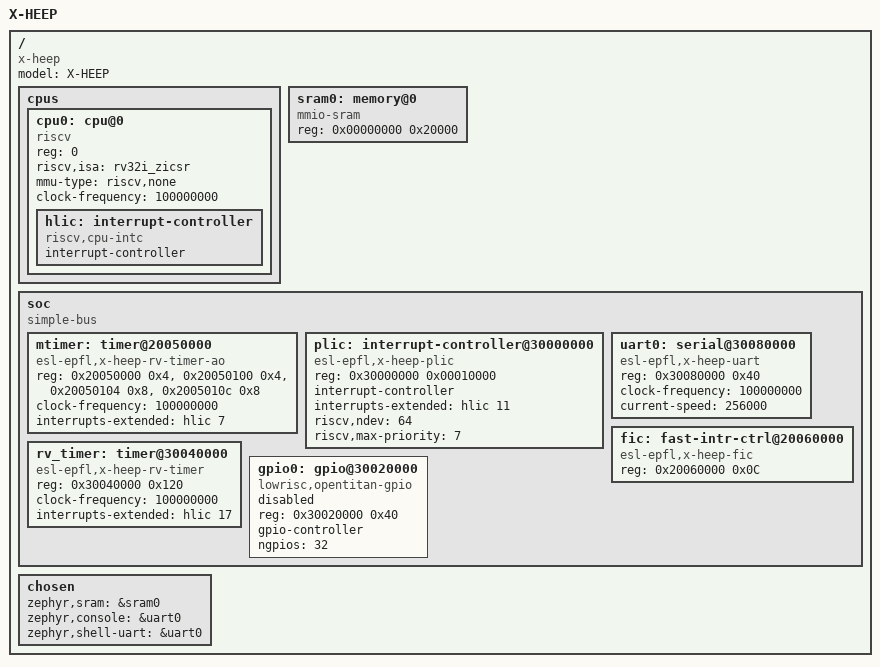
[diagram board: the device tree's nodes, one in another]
/*
 * author: rbatal (rodrigo.batal@gmail.com)
 *
 * X-HEEP Devicetree for Zephyr RTOS (core-agnostic)
 *  Applies to all X-HEEP core variants: cv32e20p, cv32e40p, cv32e40x, cv32e40px
 *
 * Notes:
 *  1 - Custom OpenTitan UART driver (differs from the one in Zephyr sources)
 *  2 - Custom OpenTitan PLIC driver (none available in Zephyr sources)
 */

/ {
	#address-cells = <1>;
	#size-cells = <1>;
	compatible = "x-heep";
	model = "X-HEEP";

	cpus {
		#address-cells = <1>;
		#size-cells = <0>;

		cpu0: cpu@0 {
			device_type = "cpu";
			compatible = "riscv";
			reg = <0>;
			riscv,isa = "rv32i_zicsr";
			mmu-type = "riscv,none";
			clock-frequency = <100000000>;
			status = "okay";

			hlic: interrupt-controller {
				compatible = "riscv,cpu-intc";
				#address-cells = <0>;
				#interrupt-cells = <1>;
				interrupt-controller;
			};
		};
	};

	sram0: memory@0 {
		device_type = "memory";
		compatible = "mmio-sram";
		reg = <0x00000000 0x20000>;  /* 128KB */
	};

	soc {
		#address-cells = <1>;
		#size-cells = <1>;
		compatible = "simple-bus";
		ranges;

		/*
		 * Machine Timer (Always-On domain)
		 * lowRISC rv_timer_ao
		 *
		 * CTRL (0x000) and CFG0 (0x100) are initialized in soc_early_init
		 * (PRE_KERNEL_1) before the riscv_machine_timer driver reads mtime.
		 * The "riscv,machine-timer" fallback compatible is required so that
		 * Zephyr's riscv_machine_timer driver binds to this node via DT_INST.
     *
		 * Interrupt routes through FIC bit 0 (kTimer_1_fic_e) to
		 * irq_i[16] - mcause 16 (hlic IRQ 16).
		 */
		mtimer: timer@20050000 {
		  compatible = "esl-epfl,x-heep-rv-timer-ao", "riscv,machine-timer";
		  reg = <0x20050000 0x4>,    /* ctrl     */
		        <0x20050100 0x4>,    /* cfg0     */
		        <0x20050104 0x8>,    /* mtime    */
		        <0x2005010c 0x8>;    /* mtimecmp */
		  reg-names = "ctrl", "cfg0", "mtime", "mtimecmp";
		  clock-frequency = <100000000>;
		  interrupts-extended = <&hlic 7>;
		  status = "okay";
		};

		/*
		 * PLIC - OpenTitan rv_plic @ 0x30000000
		 *
		 * Driven by the custom esl-epfl,x-heep-plic driver which uses
		 * the following register map:
		 *   Priority  base + 0x010  (stride 4 per source)
		 *   IE        base + 0x200
		 *   Threshold base + 0x208
		 *   CC        base + 0x20C
		 */
		plic: interrupt-controller@30000000 {
			compatible = "esl-epfl,x-heep-plic";
			reg = <0x30000000 0x00010000>;
			#address-cells = <0>;
			#interrupt-cells = <2>;
			interrupt-controller;
			interrupts-extended = <&hlic 11>;
			riscv,ndev = <64>;
			riscv,max-priority = <7>;
			status = "okay";
		};

		/*
		 * UART - OpenTitan UART at 0x30080000
		 * Using polling mode (no interrupts until PLIC driver implemented)
		 */
		uart0: serial@30080000 {
			compatible = "esl-epfl,x-heep-uart";
			reg = <0x30080000 0x40>;
			clock-frequency = <100000000>;
			current-speed = <256000>;
			/* No interrupt-parent since PLIC is disabled */
			status = "okay";
		};

		/*
		 * FIC - Fast Interrupt Controller (Always-On domain)
		 *
		 * Source N fires at mcause (16+N); the driver also controls
		 * the corresponding MIE bits at the core level.
		*/
		fic: fast-intr-ctrl@20060000 {
		  compatible = "esl-epfl,x-heep-fic";
		  reg = <0x20060000 0x0C>;
		  status = "okay";
		};

		/*
		 * rv_timer (User domain)
		 * lowRISC rv_timer
     *
		 * Same IP as rv_timer_ao but in the user peripheral domain.
		 * Interrupt routes through FIC bit 1 (kTimer_2_fic_e) to
		 * irq_i[17] - mcause 17 (hlic IRQ 17).
		*/
		rv_timer: timer@30040000 {
		  compatible = "esl-epfl,x-heep-rv-timer";
		  reg = <0x30040000 0x120>;
		  clock-frequency = <100000000>;
		  interrupts-extended = <&hlic 17>;
		  status = "okay";
		};

		/*
		 * GPIO Controller (disabled for now)
		 */
		gpio0: gpio@30020000 {
			compatible = "lowrisc,opentitan-gpio";
			reg = <0x30020000 0x40>;
			gpio-controller;
			#gpio-cells = <2>;
			ngpios = <32>;
			status = "disabled";
		};
	};

	chosen {
		zephyr,sram = &sram0;
		zephyr,console = &uart0;
		zephyr,shell-uart = &uart0;
	};
};
